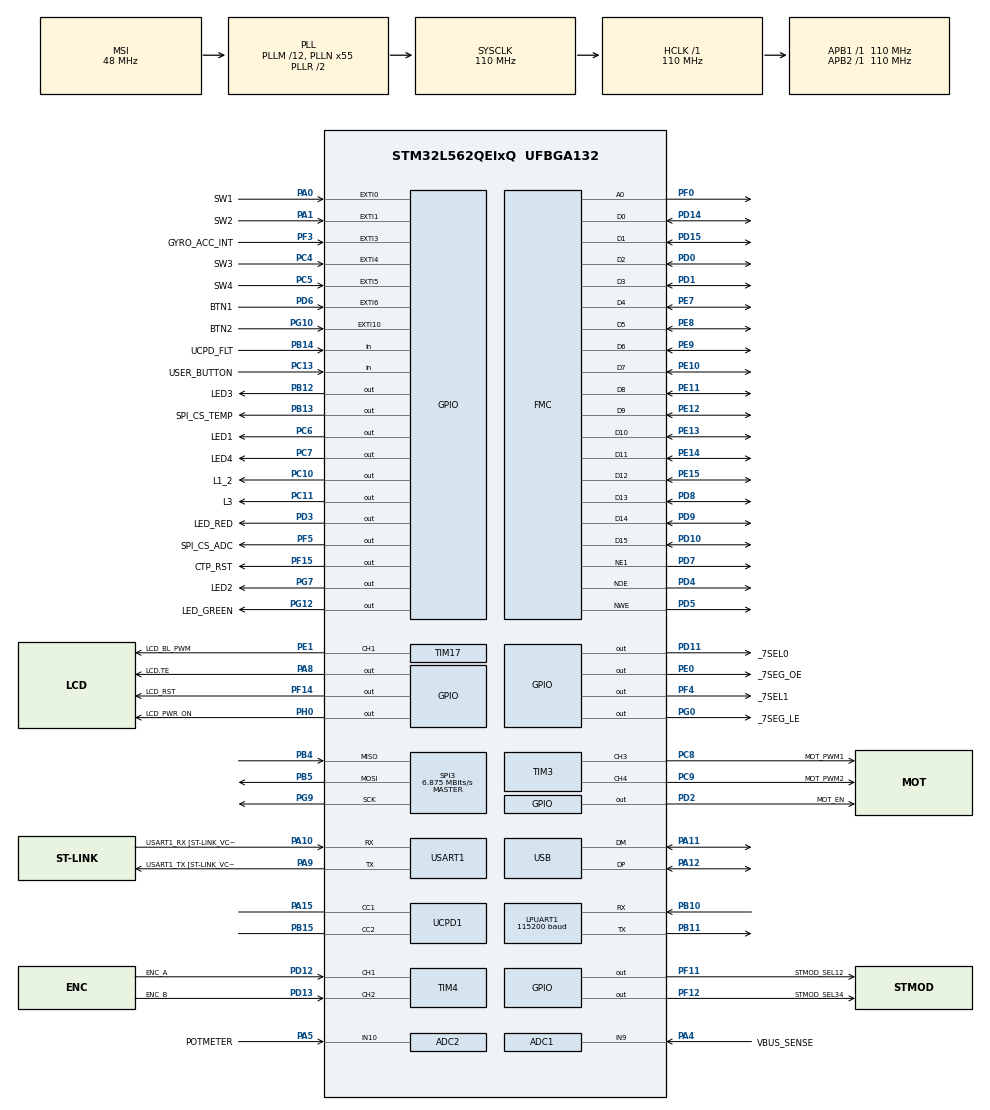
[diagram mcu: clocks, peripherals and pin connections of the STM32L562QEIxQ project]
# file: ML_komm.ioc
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ADC1.Channel-0\#ChannelRegularConversion=ADC_CHANNEL_9
ADC1.NbrOfConversionFlag=1
ADC1.OffsetNumber-0\#ChannelRegularConversion=ADC_OFFSET_NONE
ADC1.Rank-0\#ChannelRegularConversion=1
ADC1.SamplingTime-0\#ChannelRegularConversion=ADC_SAMPLETIME_2CYCLES_5
ADC1.master=1
ADC2.Channel-0\#ChannelRegularConversion=ADC_CHANNEL_10
ADC2.NbrOfConversionFlag=1
ADC2.OffsetNumber-0\#ChannelRegularConversion=ADC_OFFSET_NONE
ADC2.Rank-0\#ChannelRegularConversion=1
ADC2.SamplingTime-0\#ChannelRegularConversion=ADC_SAMPLETIME_2CYCLES_5
Dma.Request0=USART1_TX
Dma.Request1=SPI3_TX
Dma.Request2=SPI3_RX
Dma.SPI3_RX.2.Channel_PRIV_NPRIV=DMA_CHANNEL_NPRIV_DISABLE
Dma.SPI3_RX.2.Direction=DMA_PERIPH_TO_MEMORY
Dma.SPI3_RX.2.EventEnable=DISABLE
Dma.SPI3_RX.2.Instance=DMA1_Channel3
Dma.SPI3_RX.2.MemDataAlignment=DMA_MDATAALIGN_BYTE
Dma.SPI3_RX.2.MemInc=DMA_MINC_ENABLE
Dma.SPI3_RX.2.Mode=DMA_NORMAL
Dma.SPI3_RX.2.PeriphDataAlignment=DMA_PDATAALIGN_BYTE
Dma.SPI3_RX.2.PeriphInc=DMA_PINC_DISABLE
Dma.SPI3_RX.2.Polarity=HAL_DMAMUX_REQ_GEN_RISING
Dma.SPI3_RX.2.Priority=DMA_PRIORITY_LOW
Dma.SPI3_RX.2.RequestNumber=1
Dma.SPI3_RX.2.SignalID=NONE
Dma.SPI3_RX.2.SyncEnable=DISABLE
Dma.SPI3_RX.2.SyncPolarity=HAL_DMAMUX_SYNC_NO_EVENT
Dma.SPI3_RX.2.SyncRequestNumber=1
Dma.SPI3_RX.2.SyncSignalID=NONE
Dma.SPI3_TX.1.Channel_PRIV_NPRIV=DMA_CHANNEL_NPRIV_DISABLE
Dma.SPI3_TX.1.Direction=DMA_MEMORY_TO_PERIPH
Dma.SPI3_TX.1.EventEnable=DISABLE
Dma.SPI3_TX.1.Instance=DMA1_Channel2
Dma.SPI3_TX.1.MemDataAlignment=DMA_MDATAALIGN_BYTE
Dma.SPI3_TX.1.MemInc=DMA_MINC_ENABLE
Dma.SPI3_TX.1.Mode=DMA_NORMAL
Dma.SPI3_TX.1.PeriphDataAlignment=DMA_PDATAALIGN_BYTE
Dma.SPI3_TX.1.PeriphInc=DMA_PINC_DISABLE
Dma.SPI3_TX.1.Polarity=HAL_DMAMUX_REQ_GEN_RISING
Dma.SPI3_TX.1.Priority=DMA_PRIORITY_LOW
Dma.SPI3_TX.1.RequestNumber=1
Dma.SPI3_TX.1.SignalID=NONE
Dma.SPI3_TX.1.SyncEnable=DISABLE
Dma.SPI3_TX.1.SyncPolarity=HAL_DMAMUX_SYNC_NO_EVENT
Dma.SPI3_TX.1.SyncRequestNumber=1
Dma.SPI3_TX.1.SyncSignalID=NONE
Dma.USART1_TX.0.Channel_PRIV_NPRIV=DMA_CHANNEL_NPRIV_DISABLE
Dma.USART1_TX.0.Direction=DMA_MEMORY_TO_PERIPH
Dma.USART1_TX.0.EventEnable=DISABLE
Dma.USART1_TX.0.Instance=DMA1_Channel1
Dma.USART1_TX.0.MemDataAlignment=DMA_MDATAALIGN_BYTE
Dma.USART1_TX.0.MemInc=DMA_MINC_ENABLE
Dma.USART1_TX.0.Mode=DMA_NORMAL
Dma.USART1_TX.0.PeriphDataAlignment=DMA_PDATAALIGN_BYTE
Dma.USART1_TX.0.PeriphInc=DMA_PINC_DISABLE
Dma.USART1_TX.0.Polarity=HAL_DMAMUX_REQ_GEN_RISING
Dma.USART1_TX.0.Priority=DMA_PRIORITY_LOW
Dma.USART1_TX.0.RequestNumber=1
Dma.USART1_TX.0.SignalID=NONE
Dma.USART1_TX.0.SyncEnable=DISABLE
Dma.USART1_TX.0.SyncPolarity=HAL_DMAMUX_SYNC_NO_EVENT
Dma.USART1_TX.0.SyncRequestNumber=1
Dma.USART1_TX.0.SyncSignalID=NONE
LPUART1.BaudRate=115200
LPUART1.SwapParam=UART_ADVFEATURE_SWAP_DISABLE
Mcu.Family=STM32L5
Mcu.Name=STM32L562QEIxQ
Mcu.Package=UFBGA132
Mcu.TrustZone=disable
NVIC.ADC1_2_IRQn=true\:0\:0\:false\:false\:true\:true\:true\:true
NVIC.DMA1_Channel1_IRQn=true\:0\:0\:false\:false\:true\:false\:true\:true
NVIC.DMA1_Channel2_IRQn=true\:0\:0\:false\:false\:true\:false\:true\:true
NVIC.DMA1_Channel3_IRQn=true\:0\:0\:false\:false\:true\:false\:true\:true
NVIC.EXTI0_IRQn=true\:0\:0\:false\:false\:true\:true\:true\:true
NVIC.EXTI10_IRQn=true\:0\:0\:false\:false\:true\:true\:true\:true
NVIC.EXTI1_IRQn=true\:0\:0\:false\:false\:true\:true\:true\:true
NVIC.EXTI3_IRQn=true\:0\:0\:false\:false\:true\:true\:true\:true
NVIC.EXTI4_IRQn=true\:0\:0\:false\:false\:true\:true\:true\:true
NVIC.EXTI5_IRQn=true\:0\:0\:false\:false\:true\:true\:true\:true
NVIC.EXTI6_IRQn=true\:0\:0\:false\:false\:true\:true\:true\:true
NVIC.LPUART1_IRQn=true\:0\:0\:false\:false\:true\:true\:true\:true
NVIC.PriorityGroup=NVIC_PRIORITYGROUP_3
NVIC.TIM16_IRQn=true\:0\:0\:false\:false\:true\:true\:true\:true
NVIC.TIM17_IRQn=true\:0\:0\:false\:false\:true\:true\:true\:true
NVIC.USART1_IRQn=true\:0\:0\:false\:false\:true\:true\:true\:true
NVIC.USB_FS_IRQn=true\:0\:0\:false\:false\:true\:false\:true\:true
PA0.GPIO_Label=SW1
PA0.Signal=GPXTI0
PA1.GPIO_Label=SW2
PA1.Signal=GPXTI1
PA10.GPIO_Label=USART1_RX [ST-LINK_VCP_TX]
PA10.GPIO_Speed=GPIO_SPEED_FREQ_HIGH
PA10.Mode=Asynchronous
PA10.Signal=USART1_RX
PA11.Mode=Device
PA11.Signal=USB_DM
PA12.Mode=Device
PA12.Signal=USB_DP
PA13\ (JTMS/SWDIO).Mode=Trace_Asynchronous_SW
PA13\ (JTMS/SWDIO).Signal=DEBUG_JTMS-SWDIO
PA14\ (JTCK/SWCLK).Mode=Trace_Asynchronous_SW
PA14\ (JTCK/SWCLK).Signal=DEBUG_JTCK-SWCLK
PA15\ (JTDI).Mode=Source_AllSignals
PA15\ (JTDI).Signal=UCPD1_CC1
PA4.GPIO_Label=VBUS_SENSE
PA4.Signal=ADCx_IN9
PA5.GPIO_Label=POTMETER
PA5.Signal=ADCx_IN10
PA8.GPIO_Label=LCD.TE
PA8.Signal=GPIO_Output
PA9.GPIO_Label=USART1_TX [ST-LINK_VCP_RX]
PA9.GPIO_Speed=GPIO_SPEED_FREQ_HIGH
PA9.Mode=Asynchronous
PA9.Signal=USART1_TX
PB10.Mode=Asynchronous
PB10.Signal=LPUART1_RX
PB11.Mode=Asynchronous
PB11.Signal=LPUART1_TX
PB12.GPIO_Label=LED3
PB12.PinState=GPIO_PIN_SET
PB12.Signal=GPIO_Output
PB13.GPIO_Label=SPI_CS_TEMP
PB13.Signal=GPIO_Output
PB14.GPIO_Label=UCPD_FLT
PB14.Signal=GPIO_Input
PB15.Mode=Source_AllSignals
PB15.Signal=UCPD1_CC2
PB3\ (JTDO/TRACESWO).Mode=Trace_Asynchronous_SW
PB3\ (JTDO/TRACESWO).Signal=DEBUG_JTDO-SWO
PB4\ (NJTRST).Mode=Full_Duplex_Master
PB4\ (NJTRST).Signal=SPI3_MISO
PB5.Mode=Full_Duplex_Master
PB5.Signal=SPI3_MOSI
PB6.GPIO_Pu=GPIO_PULLUP
PB6.Signal=I2C1_SCL
PB7.GPIO_Pu=GPIO_PULLUP
PB7.Signal=I2C1_SDA
PC10.GPIO_Label=L1_2
PC10.PinState=GPIO_PIN_SET
PC10.Signal=GPIO_Output
PC11.GPIO_Label=L3
PC11.PinState=GPIO_PIN_SET
PC11.Signal=GPIO_Output
PC13.GPIO_Label=USER_BUTTON
PC13.Signal=GPIO_Input
PC14-OSC32_IN\ (PC14).Mode=LSE-External-Oscillator
PC14-OSC32_IN\ (PC14).Signal=RCC_OSC32_IN
PC15-OSC32_OUT\ (PC15).Mode=LSE-External-Oscillator
PC15-OSC32_OUT\ (PC15).Signal=RCC_OSC32_OUT
PC4.GPIO_Label=SW3
PC4.Signal=GPXTI4
PC5.GPIO_Label=SW4
PC5.Signal=GPXTI5
PC6.GPIO_Label=LED1
PC6.PinState=GPIO_PIN_SET
PC6.Signal=GPIO_Output
PC7.GPIO_Label=LED4
PC7.PinState=GPIO_PIN_SET
PC7.Signal=GPIO_Output
PC8.GPIO_Label=MOT_PWM1
PC8.Signal=S_TIM3_CH3
PC9.GPIO_Label=MOT_PWM2
PC9.Signal=S_TIM3_CH4
PD0.Signal=FMC_D2_DA2
PD1.Signal=FMC_D3_DA3
PD10.Signal=FMC_D15_DA15
PD11.GPIO_Label=_7SEL0
PD11.Signal=GPIO_Output
PD12.GPIO_Label=ENC_A
PD12.Signal=S_TIM4_CH1
PD13.GPIO_Label=ENC_B
PD13.Signal=S_TIM4_CH2
PD14.Signal=FMC_D0_DA0
PD15.Signal=FMC_D1_DA1
PD2.GPIO_Label=MOT_EN
PD2.PinState=GPIO_PIN_RESET
PD2.Signal=GPIO_Output
PD3.GPIO_Label=LED_RED
PD3.Signal=GPIO_Output
PD4.Signal=FMC_NOE
PD5.Signal=FMC_NWE
PD6.GPIO_Label=BTN1
PD6.Signal=GPXTI6
PD7.Mode=NorPsramChipSelect1_1
PD7.Signal=FMC_NE1
PD8.Signal=FMC_D13_DA13
PD9.Signal=FMC_D14_DA14
PE0.GPIO_Label=_7SEG_\\OE
PE0.PinState=GPIO_PIN_SET
PE0.Signal=GPIO_Output
PE1.GPIO_Label=LCD_BL_PWM
PE1.Signal=S_TIM17_CH1
PE10.Signal=FMC_D7_DA7
PE11.Signal=FMC_D8_DA8
PE12.Signal=FMC_D9_DA9
PE13.Signal=FMC_D10_DA10
PE14.Signal=FMC_D11_DA11
PE15.Signal=FMC_D12_DA12
PE7.Signal=FMC_D4_DA4
PE8.Signal=FMC_D5_DA5
PE9.Signal=FMC_D6_DA6
PF0.Signal=FMC_A0
PF11.GPIO_Label=STMOD_SEL12
PF11.PinState=GPIO_PIN_SET
PF11.Signal=GPIO_Output
PF12.GPIO_Label=STMOD_SEL34
PF12.PinState=GPIO_PIN_SET
PF12.Signal=GPIO_Output
PF14.GPIO_Label=LCD_RST
PF14.Signal=GPIO_Output
PF15.GPIO_Label=CTP_RST
PF15.Signal=GPIO_Output
PF3.GPIO_Label=GYRO_ACC_INT
PF3.Signal=GPXTI3
PF4.GPIO_Label=_7SEL1
PF4.Signal=GPIO_Output
PF5.GPIO_Label=SPI_CS_ADC
PF5.PinState=GPIO_PIN_SET
PF5.Signal=GPIO_Output
PG0.GPIO_Label=_7SEG_LE
PG0.Signal=GPIO_Output
PG10.GPIO_Label=BTN2
PG10.Signal=GPXTI10
PG12.GPIO_Label=LED_GREEN
PG12.Signal=GPIO_Output
PG7.GPIO_Label=LED2
PG7.PinState=GPIO_PIN_SET
PG7.Signal=GPIO_Output
PG9.Mode=Full_Duplex_Master
PG9.Signal=SPI3_SCK
PH0-OSC_IN\ (PH0).GPIO_Label=LCD_PWR_ON
PH0-OSC_IN\ (PH0).Signal=GPIO_Output
ProjectManager.HeapSize=0x200
ProjectManager.StackSize=0x400
ProjectManager.TargetToolchain=STM32CubeIDE
RCC.ADCFreq_Value=96000000
RCC.AHBFreq_Value=110000000
RCC.APB1Freq_Value=110000000
RCC.APB1TimFreq_Value=110000000
RCC.APB2Freq_Value=110000000
RCC.APB2TimFreq_Value=110000000
RCC.CK48CLockSelection=RCC_USBCLKSOURCE_MSI
RCC.CortexFreq_Value=110000000
RCC.HCLKFreq_Value=110000000
RCC.HSE_VALUE=8000000
RCC.HSI48_VALUE=48000000
RCC.HSI_VALUE=16000000
RCC.MSIClockRange=RCC_MSIRANGE_11
RCC.MSI_VALUE=48000000
RCC.PLLM=12
RCC.PLLN=55
RCC.PLLSAI1M=4
RCC.PLLSAI1N=48
RCC.PLLSAI1P=RCC_PLLP_DIV17
RCC.PLLSAI1Source=RCC_PLLSAI1SOURCE_HSI
RCC.SDMMCClockSelection=RCC_SDIOCLKSOURCE_CLK48
RCC.SYSCLKFreq_VALUE=110000000
RCC.SYSCLKSource=RCC_SYSCLKSOURCE_PLLCLK
RCC.USBFreq_Value=48000000
RCC.VCOOutputFreq_Value=220000000
SH.ADCx_IN10.0=ADC2_IN10,IN10-Single-Ended
SH.ADCx_IN9.0=ADC1_IN9,IN9-Single-Ended
SH.FMC_A0.0=FMC_A0,A0_1
SH.FMC_D0_DA0.0=FMC_DA0
SH.FMC_D0_DA0.1=FMC_D0,16b-d1
SH.FMC_D10_DA10.0=FMC_DA10
SH.FMC_D10_DA10.1=FMC_D10,16b-d1
SH.FMC_D11_DA11.0=FMC_DA11
SH.FMC_D11_DA11.1=FMC_D11,16b-d1
SH.FMC_D12_DA12.0=FMC_DA12
SH.FMC_D12_DA12.1=FMC_D12,16b-d1
SH.FMC_D13_DA13.0=FMC_DA13
SH.FMC_D13_DA13.1=FMC_D13,16b-d1
SH.FMC_D14_DA14.0=FMC_DA14
SH.FMC_D14_DA14.1=FMC_D14,16b-d1
SH.FMC_D15_DA15.0=FMC_DA15
SH.FMC_D15_DA15.1=FMC_D15,16b-d1
SH.FMC_D1_DA1.0=FMC_DA1
SH.FMC_D1_DA1.1=FMC_D1,16b-d1
SH.FMC_D2_DA2.0=FMC_DA2
SH.FMC_D2_DA2.1=FMC_D2,16b-d1
SH.FMC_D3_DA3.0=FMC_DA3
SH.FMC_D3_DA3.1=FMC_D3,16b-d1
SH.FMC_D4_DA4.0=FMC_DA4
SH.FMC_D4_DA4.1=FMC_D4,16b-d1
SH.FMC_D5_DA5.0=FMC_DA5
SH.FMC_D5_DA5.1=FMC_D5,16b-d1
SH.FMC_D6_DA6.0=FMC_DA6
SH.FMC_D6_DA6.1=FMC_D6,16b-d1
SH.FMC_D7_DA7.0=FMC_DA7
SH.FMC_D7_DA7.1=FMC_D7,16b-d1
SH.FMC_D8_DA8.0=FMC_DA8
SH.FMC_D8_DA8.1=FMC_D8,16b-d1
SH.FMC_D9_DA9.0=FMC_DA9
SH.FMC_D9_DA9.1=FMC_D9,16b-d1
SH.FMC_NOE.0=FMC_NOE,Lcd1
SH.FMC_NWE.0=FMC_NWE,Lcd1
SH.S_TIM17_CH1.0=TIM17_CH1,PWM Generation1 CH1
SH.S_TIM3_CH3.0=TIM3_CH3,PWM Generation3 CH3
SH.S_TIM3_CH4.0=TIM3_CH4,PWM Generation4 CH4
SH.S_TIM4_CH1.0=TIM4_CH1,Input_Capture1_from_TI1
SH.S_TIM4_CH2.0=TIM4_CH2,Input_Capture2_from_TI2
SPI3.BaudRatePrescaler=SPI_BAUDRATEPRESCALER_16
SPI3.CalculateBaudRate=6.875 MBits/s
SPI3.DataSize=SPI_DATASIZE_8BIT
SPI3.Direction=SPI_DIRECTION_2LINES
SPI3.Mode=SPI_MODE_MASTER
SPI3.VirtualType=VM_MASTER
TIM17.Channel=TIM_CHANNEL_1
TIM3.Channel-PWM\ Generation3\ CH3=TIM_CHANNEL_3
TIM3.Channel-PWM\ Generation4\ CH4=TIM_CHANNEL_4
TIM4.Channel-Input_Capture1_from_TI1=TIM_CHANNEL_1
TIM4.Channel-Input_Capture2_from_TI2=TIM_CHANNEL_2
USART1.VirtualMode-Asynchronous=VM_ASYNC
USB_DEVICE.CLASS_NAME_FS=CDC
USB_DEVICE.VirtualMode=Cdc
USB_DEVICE.VirtualModeFS=Cdc_FS
VP_ICACHE_VS_ICACHE.Mode=DirectMappedCache
VP_PWR_VS_DBSignals.Mode=DisableDeadBatterySignals
VP_PWR_VS_SECSignals.Mode=Security/Privilege
VP_TIM16_VS_ClockSourceINT.Mode=Enable_Timer
VP_TIM17_VS_ClockSourceINT.Mode=Enable_Timer
VP_USB_DEVICE_VS_USB_DEVICE_CDC_FS.Mode=CDC_FS
board=STM32L562E-DK

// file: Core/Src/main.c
/* USER CODE BEGIN Header */
/**
  ******************************************************************************
  * @file           : main.c
  * @brief          : Main program body
  ******************************************************************************
  * @attention
  *
  * Copyright (c) 2025 STMicroelectronics.
  * All rights reserved.
  *
  * This software is licensed under terms that can be found in the LICENSE file
  * in the root directory of this software component.
  * If no LICENSE file comes with this software, it is provided AS-IS.
  *
  ******************************************************************************
  */
/* USER CODE END Header */
#include "main.h"
#include "adc.h"
#include "dma.h"
#include "icache.h"
#include "usart.h"
#include "spi.h"
#include "tim.h"
#include "ucpd.h"
#include "usb_device.h"
#include "gpio.h"
#include "fmc.h"

/* USER CODE BEGIN Includes */
#include "SevenSegment.h"
#include "IMU.h"
#include "Log.h"
#include "CanCommunication.h"
/* USER CODE END Includes */

/* USER CODE BEGIN PV */
uint8_t _btn1State=0;
/* USER CODE END PV */

void SystemClock_Config(void);

int main(void)
{

  /* MCU Configuration--------------------------------------------------------*/

  /* Reset of all peripherals, Initializes the Flash interface and the Systick. */
  HAL_Init();

  /* Configure the system clock */
  SystemClock_Config();

  /* Initialize all configured peripherals */
  MX_GPIO_Init();
  MX_DMA_Init();
  MX_ADC1_Init();
  MX_FMC_Init();
  MX_ICACHE_Init();
  MX_LPUART1_UART_Init();
  MX_USART1_UART_Init();
  MX_TIM4_Init();
  MX_TIM16_Init();
  MX_TIM17_Init();
  MX_UCPD1_Init();
  MX_SPI3_Init();
  MX_TIM3_Init();
  MX_ADC2_Init();
  MX_USB_Device_Init();
  /* USER CODE BEGIN 2 */

  // TODO 2.2
  // Create a deviceId variable and store the states of switches SW1 and SW2 in the lower two bits.
  uint8_t switch1=HAL_GPIO_ReadPin(SW1_GPIO_Port,SW1_Pin);
  uint8_t switch2=HAL_GPIO_ReadPin(SW2_GPIO_Port,SW2_Pin);
  uint8_t deviceId = switch1 | (switch2<<1);
  Log_Init(1);

  // TODO 1.3
  // Call IMU_Init() function!
  IMU_Init();

  // TODO 1.4
  // Call the IMU calibration function, e.g., with a 1000ms delay: IMU_CalibrateGyro()
  // Check if the gyroscope measurement data has improved!
  IMU_CalibrateGyro(1000);

  // TODO 2.1
  // Call CanCommunication_Init() function!
  CanCommunication_Init(deviceId);
  Log("\r\nHello STM32 kommunikacio!\r\n");

  SevenSegment_Init();

  /* USER CODE END 2 */
  IMUData_t current_measurement;
  uint8_t prevState=0;
  uint8_t curState;
  /* Infinite loop */
  while (1)
  {

    /* USER CODE BEGIN 3 */
	 // TODO 1.3
	 // Declare a structure instance for the IMU data: IMUData_t
	 // Try to update the IMU data
	 // If successful, write the acceleration and angular velocity data as text into a char[]!
	 // Convert the float type to int, scale the data, e.g., by 1000 times
	 // Write the data via Log() to the debugger UART, check the data
  if (IMU_Update(&current_measurement)) {
  char buffer[100];
  int accel_x = (int)(current_measurement.Accelero_X * 1000);
  int accel_y = (int)(current_measurement.Accelero_Y * 1000);
  int accel_z = (int)(current_measurement.Accelero_Z * 1000);
  int gyro_x = (int)(current_measurement.Gyro_X * 1000);
  int gyro_y = (int)(current_measurement.Gyro_Y * 1000);
  int gyro_z = (int)(current_measurement.Gyro_Z * 1000);
  sprintf(buffer, "Ax: %d Ay: %d Az: %d Gx: %d Gy: %d Gz: %d \r\n", accel_x,
  accel_y,accel_z,gyro_x, gyro_y, gyro_z);
  Log(buffer);
  }

  AppCanMessage_t msg;
  char buffer2[100];
  if (CanCommunication_Receive(0,&msg))
  {
  sprintf(buffer2,"MessageID:%x",msg.Id);
  Log(buffer2);
  SevenSegment_UpdateValueHex(msg.Id);
  }
  // TODO 2.3
  // Check for the BTN1 button press, on the rising edge:
  // Use an AppCanMessage_t instance,
  // Set the ID to 0x010 and copy the device ID into the lower 2 bits
  // Write the state of the switches into the lower 4 bits of the data
  // Send the message using the CanCommunication_Send function.
  curState=HAL_GPIO_ReadPin(BTN1_GPIO_Port,BTN1_Pin);
  AppCanMessage_t send_msg;
  if (prevState==0 && curState)
  {
  send_msg.Id=0x010 | deviceID;
  uint8_t sw1=HAL_GPIO_ReadPin(SW1_GPIO_Port,SW1_Pin);
  uint8_t sw2=HAL_GPIO_ReadPin(SW2_GPIO_Port,SW2_Pin);
  uint8_t sw3=HAL_GPIO_ReadPin(SW3_GPIO_Port,SW3_Pin);
  uint8_t sw4=HAL_GPIO_ReadPin(SW4_GPIO_Port,SW4_Pin);
  send_msg.Message= (sw1<<3)|(sw2<<2)|(sw3<<1)|(sw4<<0);
  CanCommunication_Send(&send_msg);
  }
  prevState=curState;
  CanCommunication_Loop();
  SevenSegment_Loop();

  }
}

  /* USER CODE END 3 */

void SystemClock_Config(void)
{
  RCC_OscInitTypeDef RCC_OscInitStruct = {0};
  RCC_ClkInitTypeDef RCC_ClkInitStruct = {0};

  /** Configure the main internal regulator output voltage
  */
  if (HAL_PWREx_ControlVoltageScaling(PWR_REGULATOR_VOLTAGE_SCALE0) != HAL_OK)
  {
    Error_Handler();
  }

  /** Configure LSE Drive Capability
  */
  HAL_PWR_EnableBkUpAccess();
  __HAL_RCC_LSEDRIVE_CONFIG(RCC_LSEDRIVE_LOW);

  /** Initializes the RCC Oscillators according to the specified parameters
  * in the RCC_OscInitTypeDef structure.
  */
  RCC_OscInitStruct.OscillatorType = RCC_OSCILLATORTYPE_HSI|RCC_OSCILLATORTYPE_LSE
                              |RCC_OSCILLATORTYPE_MSI;
  RCC_OscInitStruct.LSEState = RCC_LSE_ON;
  RCC_OscInitStruct.HSIState = RCC_HSI_ON;
  RCC_OscInitStruct.HSICalibrationValue = RCC_HSICALIBRATION_DEFAULT;
  RCC_OscInitStruct.MSIState = RCC_MSI_ON;
  RCC_OscInitStruct.MSICalibrationValue = RCC_MSICALIBRATION_DEFAULT;
  RCC_OscInitStruct.MSIClockRange = RCC_MSIRANGE_11;
  RCC_OscInitStruct.PLL.PLLState = RCC_PLL_ON;
  RCC_OscInitStruct.PLL.PLLSource = RCC_PLLSOURCE_MSI;
  RCC_OscInitStruct.PLL.PLLM = 12;
  RCC_OscInitStruct.PLL.PLLN = 55;
  RCC_OscInitStruct.PLL.PLLP = RCC_PLLP_DIV7;
  RCC_OscInitStruct.PLL.PLLQ = RCC_PLLQ_DIV2;
  RCC_OscInitStruct.PLL.PLLR = RCC_PLLR_DIV2;
  if (HAL_RCC_OscConfig(&RCC_OscInitStruct) != HAL_OK)
  {
    Error_Handler();
  }

  /** Initializes the CPU, AHB and APB buses clocks
  */
  RCC_ClkInitStruct.ClockType = RCC_CLOCKTYPE_HCLK|RCC_CLOCKTYPE_SYSCLK
                              |RCC_CLOCKTYPE_PCLK1|RCC_CLOCKTYPE_PCLK2;
  RCC_ClkInitStruct.SYSCLKSource = RCC_SYSCLKSOURCE_PLLCLK;
  RCC_ClkInitStruct.AHBCLKDivider = RCC_SYSCLK_DIV1;
  RCC_ClkInitStruct.APB1CLKDivider = RCC_HCLK_DIV1;
  RCC_ClkInitStruct.APB2CLKDivider = RCC_HCLK_DIV1;

  if (HAL_RCC_ClockConfig(&RCC_ClkInitStruct, FLASH_LATENCY_5) != HAL_OK)
  {
    Error_Handler();
  }

  /** Enable MSI Auto calibration
  */
  HAL_RCCEx_EnableMSIPLLMode();
}

void Error_Handler(void)
{
  __disable_irq();
  while (1)
  {
  }
}
